VERSION ""

NS_ :

BS_:

BU_:
VAL_TABLE_ Radar_Match_Confidence 5 "High match" 4 "Match3" 3 "Match2" 2 "Match1" 1 "Multi match" 0 "Not match" ;
VAL_TABLE_ CIPV_Flag 1 "CIPV" 0 "Not CIPV" ;
VAL_TABLE_ Obstacle_Lane 3 "Invalid signal" 2 "Next lane" 1 "Ego lane" 0 "Not assigned" ;
VAL_TABLE_ Obstacle_Valid 2 "Older valid" 1 "New valid" ;
VAL_TABLE_ Obstacle_Status 5 "Parked" 4 "Oncoming" 3 "Moving" 2 "Stopped" 1 "Standing" 0 "Undefined" ;
VAL_TABLE_ Obstacle_Type 4 "Bicycle" 3 "Ped" 2 "Bike" 1 "Truck" 0 "Vehicle" ;
VAL_TABLE_ Cut_in_and_out 4 "Cut out" 3 "Cut in" 2 "Out host line" 1 "In host line" 0 "Undefined" ;
VAL_TABLE_ Blinkers_status 4 "Both" 3 "Right" 2 "Left" 1 "Off" 0 "Unavaliable" ;
VAL_TABLE_ Failsafe 2 "Blur Image" 1 "Low sun" 0 "No failsafe" ;
VAL_TABLE_ Obstacle_moving_statue 15 "Not calculated" 3 "Driver decision is required" 2 "Undecided" 1 "Go" 0 "Stop" ;
VAL_TABLE_ Available 1 "Available" 0 "Unavailable" ;
VAL_TABLE_ Bool 1 "True" 0 "False" ;

BO_ 1792 Interface: 8 Vector__XXX
 SG_ Sound_Type : 0|3@1+ (1,0) [0|0] "" Vector__XXX

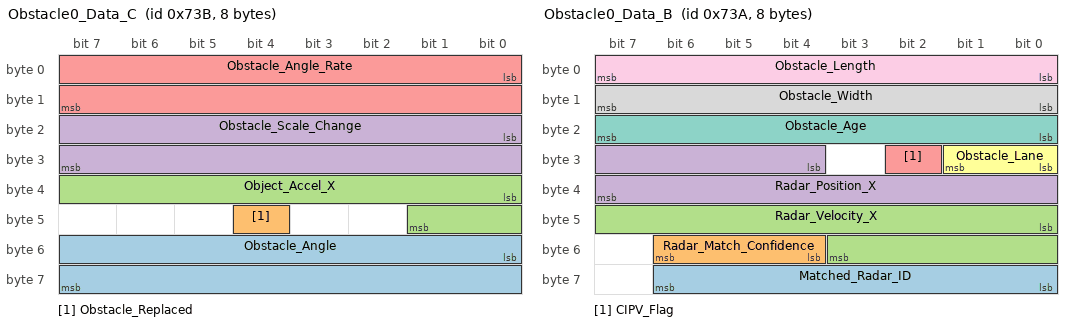
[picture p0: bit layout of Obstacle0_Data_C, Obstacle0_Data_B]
BO_ 1851 Obstacle0_Data_C: 8 Vector__XXX
 SG_ Obstacle_Angle : 48|16@1- (0.01,0) [-327.68|327.67] "deg" Vector__XXX
 SG_ Obstacle_Replaced : 44|1@1+ (1,0) [0|1] "" Vector__XXX
 SG_ Object_Accel_X : 32|10@1- (0.03,0) [-14.97|14.97] "" Vector__XXX
 SG_ Obstacle_Scale_Change : 16|16@1- (0.0002,0) [-6.5536|6.5534] "pix/s" Vector__XXX
 SG_ Obstacle_Angle_Rate : 0|16@1- (0.01,0) [-327.68|327.67] "deg/s" Vector__XXX

BO_ 1850 Obstacle0_Data_B: 8 Vector__XXX
 SG_ Matched_Radar_ID : 56|7@1+ (1,0) [0|127] "" Vector__XXX
 SG_ Radar_Match_Confidence : 52|3@1+ (1,0) [0|7] "" Vector__XXX
 SG_ Radar_Velocity_X : 40|12@1- (0.0625,0) [-127.93|127.93] "" Vector__XXX
 SG_ Radar_Position_X : 28|12@1+ (0.0625,0) [0|250] "m" Vector__XXX
 SG_ CIPV_Flag : 26|1@1+ (1,0) [0|1] "" Vector__XXX
 SG_ Obstacle_Lane : 24|2@1+ (1,0) [0|3] "" Vector__XXX
 SG_ Obstacle_Age : 16|8@1+ (1,0) [0|255] "" Vector__XXX
 SG_ Obstacle_Width : 8|8@1+ (0.05,0) [0|12.5] "m" Vector__XXX
 SG_ Obstacle_Length : 0|8@1+ (0.5,0) [0|31] "m" Vector__XXX

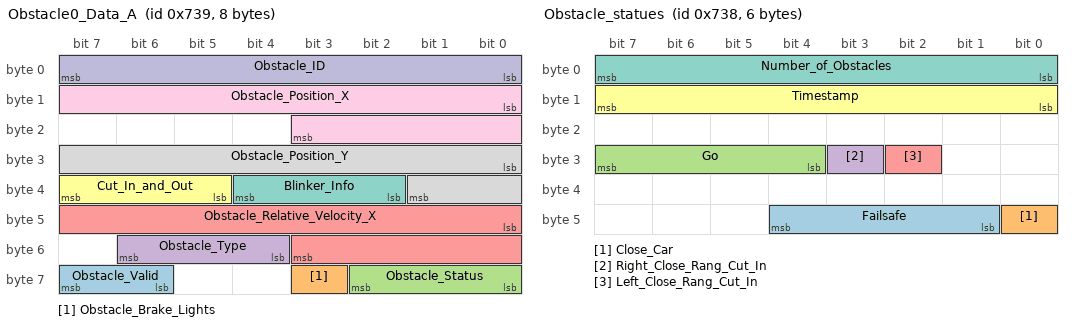
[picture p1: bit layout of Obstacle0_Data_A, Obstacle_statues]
BO_ 1849 Obstacle0_Data_A: 8 Vector__XXX
 SG_ Obstacle_Valid : 62|2@1+ (1,0) [0|3] "" Vector__XXX
 SG_ Obstacle_Brake_Lights : 59|1@1+ (1,0) [0|1] "" Vector__XXX
 SG_ Obstacle_Status : 56|3@1+ (1,0) [0|7] "" Vector__XXX
 SG_ Obstacle_Type : 52|3@1+ (1,0) [0|7] "" Vector__XXX
 SG_ Obstacle_Relative_Velocity_X : 40|12@1- (0.0625,0) [-127.93|127.93] "m/s" Vector__XXX
 SG_ Cut_In_and_Out : 37|3@1+ (1,0) [0|7] "" Vector__XXX
 SG_ Blinker_Info : 34|3@1+ (1,0) [0|7] "" Vector__XXX
 SG_ Obstacle_Position_Y : 24|10@1- (0.0625,0) [-31.93|31.93] "m" Vector__XXX
 SG_ Obstacle_Position_X : 8|12@1+ (0.0625,0) [0|250] "m" Vector__XXX
 SG_ Obstacle_ID : 0|8@1+ (1,0) [0|63] "" Vector__XXX

BO_ 1848 Obstacle_statues: 6 Vector__XXX
 SG_ Failsafe : 41|4@1+ (1,0) [0|7] "" Vector__XXX
 SG_ Close_Car : 40|1@1+ (1,0) [0|1] "" Vector__XXX
 SG_ Go : 28|4@1+ (1,0) [0|15] "" Vector__XXX
 SG_ Right_Close_Rang_Cut_In : 27|1@1+ (1,0) [0|1] "" Vector__XXX
 SG_ Left_Close_Rang_Cut_In : 26|1@1+ (1,0) [0|1] "" Vector__XXX
 SG_ Timestamp : 8|8@1+ (1,0) [0|255] "ms" Vector__XXX
 SG_ Number_of_Obstacles : 0|8@1+ (1,0) [0|255] "" Vector__XXX

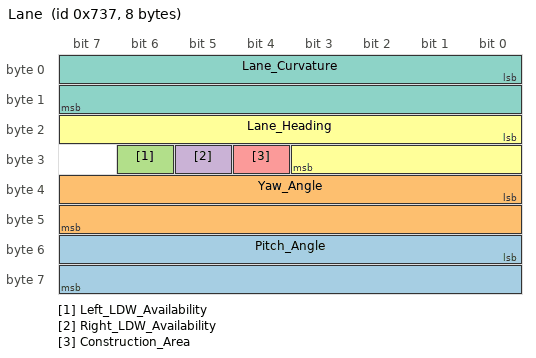
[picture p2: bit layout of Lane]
BO_ 1847 Lane: 8 Vector__XXX
 SG_ Pitch_Angle : 48|16@1+ (1.9073486328125E-006,-0.0624980926513672) [-0.05|0.05] "rad" Vector__XXX
 SG_ Yaw_Angle : 32|16@1+ (0.0009765625,-31.9990234375) [-31.9990234375|32] "rad" Vector__XXX
 SG_ Left_LDW_Availability : 30|1@1+ (1,0) [0|1] "" Vector__XXX
 SG_ Right_LDW_Availability : 29|1@1+ (1,0) [0|1] "" Vector__XXX
 SG_ Construction_Area : 28|1@1+ (1,0) [0|1] "" Vector__XXX
 SG_ Lane_Heading : 16|12@1- (0.0005,0) [-1|1] "" Vector__XXX
 SG_ Lane_Curvature : 0|16@1- (3.81E-006,0) [-0.12|0.12] "1/m" Vector__XXX

CM_ BO_ 1851 "This message contains obstacle detection information and measurements";
CM_ SG_ 1851 Obstacle_Angle "The angle error can have errors with correlation to the distance measurements errorAngle rate of Center of Obstacle in degrees/sec. 
A negative angle rate indicates that the obstacle has moved to the left 
This value is calculated  point in two consecutive frames.";
CM_ SG_ 1851 Obstacle_Replaced "0 Not replaced in this frame
1 Replace in this frame";
CM_ BO_ 1850 "This message contains obstacle detection information and measurements";
CM_ SG_ 1850 Matched_Radar_ID "ID of Primary radar target matched to the vision target if applicable.";
CM_ SG_ 1850 Radar_Match_Confidence "0: No match
1: Multi match, radar does not describe well the vision obstacle.
2-4: vision - radar match, with bounded error higher match confidence yield smaller error
5: high confidence match, with small error between Radar and vision measurement";
CM_ SG_ 1850 Radar_Velocity_X "The longitude velocity of the radar target matched to the vision targets (if applicable). 
If no radar target is matched, the value will be 0xFFF";
CM_ SG_ 1850 Radar_Position_X "The longitude position of the primary radar target matched to the vision target (if applicable), 
distance is given in relative to the reference point and not the camera. 
If no radar target is matched, the value will be 0xFFFh.";
CM_ SG_ 1850 CIPV_Flag "This value is calculated from the obstacle position and
 the lane detection or the headway model (yaw rate based or vision based) of the vehicle.
 The lane assignment decision usually takes up to 5 frames from the first detection of the obstacle";
CM_ SG_ 1850 Obstacle_Age "The age of the obstacle (in frames). 
This value starts at 1 when the obstacle is first detected, and increments in 1 each frame. 
The value reported is minimum (realAge, 254), which means that it remains 254 if the age is larger than that number.";
CM_ SG_ 1850 Obstacle_Width "This value is calculated from the width in the image and the obstacle distance. 
filtered  error < 10% of the width in 90% of the cases. 
At night, the width measured is between the obstacle¡¯s taillights.";
CM_ SG_ 1850 Obstacle_Length "The length of the obstacle (longitude axis). 
Updated only for next lane vehicles that are fully seen, and only if the system has found the front edge of the vehicle. 
We don¡¯t have recent information regarding the signal¡¯s accuracy.";
CM_ BO_ 1849 "This message contains obstacle detection information and measurements";
CM_ SG_ 1849 Obstacle_Type "Enumerator signal, which indicates the object's classification";
CM_ SG_ 1849 Obstacle_Relative_Velocity_X "The relative longitude velocity of the obstacle. 
This field is computed from the obstacle scale change in the image.
The value is a single frame value";
CM_ SG_ 1849 Blinker_Info "Indicated Blinkers status";
CM_ SG_ 1849 Obstacle_Position_X "relative to the reference point. computed from the image position of the obstacle and from the detected width of the obstacle. 
value is filtered to provide smooth measurements. error is below 10% or 2 meters (the larger of the two) in ~85% of the cases.";
CM_ SG_ 1849 Obstacle_ID "New obstacles are given the last used free ID";
CM_ BO_ 1848 "This message contains the number of obstacles, the timestamp and the application version. 
Obstacles can be vehicles, Motorcycles or pedestrians.";
CM_ SG_ 1848 Close_Car "Indication whether we detect a close car in front of the host vehicle or not.";
CM_ SG_ 1848 Go "Reports only values of 0 or 1 or 15
Reports Stop or Go decisions only when the own vehicle is standing
 (having ego speed of less than 0.1 meters per second). Otherwise, the value 15 is reported.";
CM_ SG_ 1848 Timestamp "Only the lowest 8 bits of the timestamp is given. The timestamp source is from the EyeQ image grabbing";
CM_ BO_ 1847 "The message contains the Lane information and measurements";
BA_DEF_ SG_  "GenSigSendType" ENUM  "Cyclic","OnWrite","OnWriteWithRepetition","OnChange","OnChangeWithRepetition","IfActive","IfActiveWithRepetition","NoSigSendType";
BA_DEF_  "DBName" STRING ;
BA_DEF_ BO_  "GenMsgSendType" ENUM  "Cyclic","not_used","not_used","not_used","not_used","Cyclic","not_used","IfActive","NoMsgSendType";
BA_DEF_DEF_  "GenSigSendType" "Cyclic";
BA_DEF_DEF_  "DBName" "";
BA_DEF_DEF_  "GenMsgSendType" "NoMsgSendType";
BA_ "DBName" "Mobileye";
VAL_ 1851 Obstacle_Replaced 1 "Replaced" 0 "Not replaced" ;
VAL_ 1850 Radar_Match_Confidence 5 "High match" 4 "Match3" 3 "Match2" 2 "Match1" 1 "Multi match" 0 "Not match" ;
VAL_ 1850 CIPV_Flag 1 "CIPV" 0 "Not CIPV" ;
VAL_ 1850 Obstacle_Lane 3 "Invalid signal" 2 "Next lane" 1 "Ego lane" 0 "Not assigned" ;
VAL_ 1849 Obstacle_Valid 2 "Older valid" 1 "New valid" ;
VAL_ 1849 Obstacle_Brake_Lights 1 "On" 0 "Off" ;
VAL_ 1849 Obstacle_Status 5 "Parked" 4 "Oncoming" 3 "Moving" 2 "Stopped" 1 "Standing" 0 "Undefined" ;
VAL_ 1849 Obstacle_Type 4 "Bicycle" 3 "Ped" 2 "Bike" 1 "Truck" 0 "Vehicle" ;
VAL_ 1849 Cut_In_and_Out 4 "Cut out" 3 "Cut in" 2 "Out host line" 1 "In host line" 0 "Undefined" ;
VAL_ 1849 Blinker_Info 4 "Both" 3 "Right" 2 "Left" 1 "Off" 0 "Unavaliable" ;
VAL_ 1848 Failsafe 2 "Blur Image" 1 "Low sun" 0 "No failsafe" ;
VAL_ 1848 Close_Car 1 "Close car exists" 0 "No close car" ;
VAL_ 1848 Go 15 "Not calculated" 3 "Driver decision is required" 2 "Undecided" 1 "Go" 0 "Stop" ;
VAL_ 1848 Right_Close_Rang_Cut_In 1 "True" 0 "False" ;
VAL_ 1848 Left_Close_Rang_Cut_In 1 "True" 0 "False" ;
VAL_ 1847 Left_LDW_Availability 1 "Available" 0 "Unavailable" ;
VAL_ 1847 Right_LDW_Availability 1 "Available" 0 "Unavailable" ;
VAL_ 1847 Construction_Area 1 "True" 0 "False" ;
